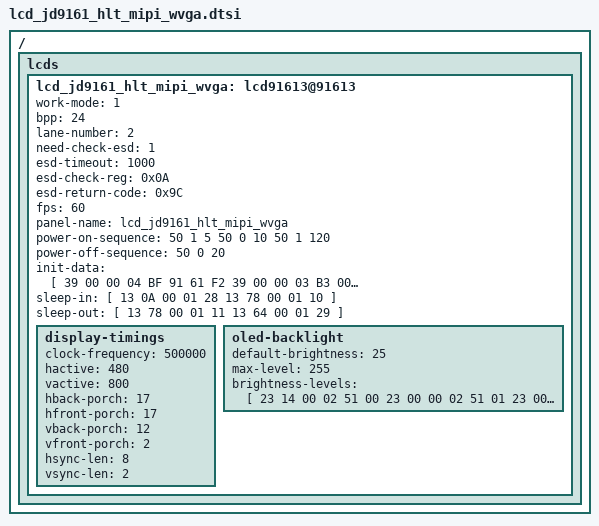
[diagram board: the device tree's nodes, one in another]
/ { lcds {
	lcd_jd9161_hlt_mipi_wvga: lcd91613@91613 {

		work-mode = <1>;
		bpp = <24>;
		lane-number = <2>;
		need-check-esd = <1>;
		esd-timeout = <1000>;
		esd-check-reg = <0x0A>;
		esd-return-code = <0x9C>;
		fps = <60>;
		panel-name = "lcd_jd9161_hlt_mipi_wvga";
		power-on-sequence = <
					50  1  5
					50  0  10
					50  1  120
					>;
		power-off-sequence = <
					50  0  20
					>;
		init-data = [
			39 00 00 04 BF 91 61 F2
			39 00 00 03 B3 00 BD
			39 00 00 03 B4 00 BF
			39 00 00 07 B8 00 BF 01 00 BF 01
			39 00 00 04 BA 3E 23 00
			23 78 00 02 C3 02
			39 00 00 03 C4 00 64
			39 00 00 27 C8 7F 78 68 5A 49 34 34 1C 37 38 3B 5E 52 63 5C 64 5E 58 4E 7F 78 68 5A 49 34 34 1C 37 38 3B 5E 52 63 5C 64 5E 58 4E
			39 00 00 0A C7 00 01 32 05 65 2B 12 A5 A5
			39 00 00 11 D4 1E 1F 17 37 06 04 0A 08 00 02 1F 1F 1F 1F 1F 1F
			39 00 00 11 D5 1E 1F 17 37 07 05 0B 09 01 03 1F 1F 1F 1F 1F 1F
			39 00 00 11 D6 1F 1E 17 17 07 09 0B 05 03 01 1F 1F 1F 1F 1F 1F
			39 00 00 11 D7 1F 1E 17 17 06 08 0A 04 02 00 1F 1F 1F 1F 1F 1F
			39 00 00 15 D8 20 00 00 30 03 30 01 02 00 01 02 06 70 00 00 73 07 06 70 08
			39 00 00 14 D9 00 0A 0A 80 00 00 06 7B 00 80 00 33 6A 1F 00 00 00 03 7B
			23 05 00 02 53 24
			23 05 00 02 55 00
			23 05 00 02 51 00
			13 78 00 01 11
			13 0A 00 01 29
			];
		sleep-in = [
			13 0A 00 01 28
			13 78 00 01 10
			];
		sleep-out = [
			13 78 00 01 11
			13 64 00 01 29
			];
		display-timings {
			clock-frequency = <500000>;
			hactive = <480>;
			vactive = <800>;
			hback-porch = <17>;
			hfront-porch = <17>;
			vback-porch = <12>;
			vfront-porch = <2>;
			hsync-len = <8>;
			vsync-len = <2>;
		};
		oled-backlight {
			default-brightness = <25>;
			max-level = <255>;
			brightness-levels = [
				23 14 00 02 51 00
				23 00 00 02 51 01
				23 00 00 02 51 02
				23 00 00 02 51 03
				23 00 00 02 51 04
				23 00 00 02 51 05
				23 00 00 02 51 06
				23 00 00 02 51 07
				23 00 00 02 51 08
				23 00 00 02 51 09
				23 00 00 02 51 0a
				23 00 00 02 51 0b
				23 00 00 02 51 0c
				23 00 00 02 51 0d
				23 00 00 02 51 0e
				23 00 00 02 51 0f
				23 00 00 02 51 10
				23 00 00 02 51 11
				23 00 00 02 51 12
				23 00 00 02 51 13
				23 00 00 02 51 14
				23 00 00 02 51 15
				23 00 00 02 51 16
				23 00 00 02 51 17
				23 00 00 02 51 18
				23 00 00 02 51 19
				23 00 00 02 51 1a
				23 00 00 02 51 1b
				23 00 00 02 51 1c
				23 00 00 02 51 1d
				23 00 00 02 51 1e
				23 00 00 02 51 1f
				23 00 00 02 51 20
				23 00 00 02 51 21
				23 00 00 02 51 22
				23 00 00 02 51 23
				23 00 00 02 51 24
				23 00 00 02 51 25
				23 00 00 02 51 26
				23 00 00 02 51 27
				23 00 00 02 51 28
				23 00 00 02 51 29
				23 00 00 02 51 2a
				23 00 00 02 51 2b
				23 00 00 02 51 2c
				23 00 00 02 51 2d
				23 00 00 02 51 2e
				23 00 00 02 51 2f
				23 00 00 02 51 30
				23 00 00 02 51 31
				23 00 00 02 51 32
				23 00 00 02 51 33
				23 00 00 02 51 34
				23 00 00 02 51 35
				23 00 00 02 51 36
				23 00 00 02 51 37
				23 00 00 02 51 38
				23 00 00 02 51 39
				23 00 00 02 51 3a
				23 00 00 02 51 3b
				23 00 00 02 51 3c
				23 00 00 02 51 3d
				23 00 00 02 51 3e
				23 00 00 02 51 3f
				23 00 00 02 51 40
				23 00 00 02 51 41
				23 00 00 02 51 42
				23 00 00 02 51 43
				23 00 00 02 51 44
				23 00 00 02 51 45
				23 00 00 02 51 46
				23 00 00 02 51 47
				23 00 00 02 51 48
				23 00 00 02 51 49
				23 00 00 02 51 4a
				23 00 00 02 51 4b
				23 00 00 02 51 4c
				23 00 00 02 51 4d
				23 00 00 02 51 4e
				23 00 00 02 51 4f
				23 00 00 02 51 50
				23 00 00 02 51 51
				23 00 00 02 51 52
				23 00 00 02 51 53
				23 00 00 02 51 54
				23 00 00 02 51 55
				23 00 00 02 51 56
				23 00 00 02 51 57
				23 00 00 02 51 58
				23 00 00 02 51 59
				23 00 00 02 51 5a
				23 00 00 02 51 5b
				23 00 00 02 51 5c
				23 00 00 02 51 5d
				23 00 00 02 51 5e
				23 00 00 02 51 5f
				23 00 00 02 51 60
				23 00 00 02 51 61
				23 00 00 02 51 62
				23 00 00 02 51 63
				23 00 00 02 51 64
				23 00 00 02 51 65
				23 00 00 02 51 66
				23 00 00 02 51 67
				23 00 00 02 51 68
				23 00 00 02 51 69
				23 00 00 02 51 6a
				23 00 00 02 51 6b
				23 00 00 02 51 6c
				23 00 00 02 51 6d
				23 00 00 02 51 6e
				23 00 00 02 51 6f
				23 00 00 02 51 70
				23 00 00 02 51 71
				23 00 00 02 51 72
				23 00 00 02 51 73
				23 00 00 02 51 74
				23 00 00 02 51 75
				23 00 00 02 51 76
				23 00 00 02 51 77
				23 00 00 02 51 78
				23 00 00 02 51 79
				23 00 00 02 51 7a
				23 00 00 02 51 7b
				23 00 00 02 51 7c
				23 00 00 02 51 7d
				23 00 00 02 51 7e
				23 00 00 02 51 7f
				23 00 00 02 51 80
				23 00 00 02 51 81
				23 00 00 02 51 82
				23 00 00 02 51 83
				23 00 00 02 51 84
				23 00 00 02 51 85
				23 00 00 02 51 86
				23 00 00 02 51 87
				23 00 00 02 51 88
				23 00 00 02 51 89
				23 00 00 02 51 8a
				23 00 00 02 51 8b
				23 00 00 02 51 8c
				23 00 00 02 51 8d
				23 00 00 02 51 8e
				23 00 00 02 51 8f
				23 00 00 02 51 90
				23 00 00 02 51 91
				23 00 00 02 51 92
				23 00 00 02 51 93
				23 00 00 02 51 94
				23 00 00 02 51 95
				23 00 00 02 51 96
				23 00 00 02 51 97
				23 00 00 02 51 98
				23 00 00 02 51 99
				23 00 00 02 51 9a
				23 00 00 02 51 9b
				23 00 00 02 51 9c
				23 00 00 02 51 9d
				23 00 00 02 51 9e
				23 00 00 02 51 9f
				23 00 00 02 51 a0
				23 00 00 02 51 a1
				23 00 00 02 51 a2
				23 00 00 02 51 a3
				23 00 00 02 51 a4
				23 00 00 02 51 a5
				23 00 00 02 51 a6
				23 00 00 02 51 a7
				23 00 00 02 51 a8
				23 00 00 02 51 a9
				23 00 00 02 51 aa
				23 00 00 02 51 ab
				23 00 00 02 51 ac
				23 00 00 02 51 ad
				23 00 00 02 51 ae
				23 00 00 02 51 af
				23 00 00 02 51 b0
				23 00 00 02 51 b1
				23 00 00 02 51 b2
				23 00 00 02 51 b3
				23 00 00 02 51 b4
				23 00 00 02 51 b5
				23 00 00 02 51 b6
				23 00 00 02 51 b7
				23 00 00 02 51 b8
				23 00 00 02 51 b9
				23 00 00 02 51 ba
				23 00 00 02 51 bb
				23 00 00 02 51 bc
				23 00 00 02 51 bd
				23 00 00 02 51 be
				23 00 00 02 51 bf
				23 00 00 02 51 c0
				23 00 00 02 51 c1
				23 00 00 02 51 c2
				23 00 00 02 51 c3
				23 00 00 02 51 c4
				23 00 00 02 51 c5
				23 00 00 02 51 c6
				23 00 00 02 51 c7
				23 00 00 02 51 c8
				23 00 00 02 51 c9
				23 00 00 02 51 ca
				23 00 00 02 51 cb
				23 00 00 02 51 cc
				23 00 00 02 51 cd
				23 00 00 02 51 ce
				23 00 00 02 51 cf
				23 00 00 02 51 d0
				23 00 00 02 51 d1
				23 00 00 02 51 d2
				23 00 00 02 51 d3
				23 00 00 02 51 d4
				23 00 00 02 51 d5
				23 00 00 02 51 d6
				23 00 00 02 51 d7
				23 00 00 02 51 d8
				23 00 00 02 51 d9
				23 00 00 02 51 da
				23 00 00 02 51 db
				23 00 00 02 51 dc
				23 00 00 02 51 dd
				23 00 00 02 51 de
				23 00 00 02 51 df
				23 00 00 02 51 e0
				23 00 00 02 51 e1
				23 00 00 02 51 e2
				23 00 00 02 51 e3
				23 00 00 02 51 e4
				23 00 00 02 51 e5
				23 00 00 02 51 e6
				23 00 00 02 51 e7
				23 00 00 02 51 e8
				23 00 00 02 51 e9
				23 00 00 02 51 ea
				23 00 00 02 51 eb
				23 00 00 02 51 ec
				23 00 00 02 51 ed
				23 00 00 02 51 ee
				23 00 00 02 51 ef
				23 00 00 02 51 f0
				23 00 00 02 51 f1
				23 00 00 02 51 f2
				23 00 00 02 51 f3
				23 00 00 02 51 f4
				23 00 00 02 51 f5
				23 00 00 02 51 f6
				23 00 00 02 51 f7
				23 00 00 02 51 f8
				23 00 00 02 51 f9
				23 00 00 02 51 fa
				23 00 00 02 51 fb
				23 00 00 02 51 fc
				23 00 00 02 51 fd
				23 00 00 02 51 fe
				23 00 00 02 51 ff
			];
		};
	};
};};

